# MKE15Z7 register map
Vendor: Freescale Semiconductor, Inc.; Series: Kinetis_E; File version: 1.6
CPU: CM0PLUS r0p0, little endian, no MPU, no FPU, VTOR, 2 interrupt priority bits
Registers are 32-bit, read-write, reset 0x0 unless marked. A register's access mark holds for its fields unless they carry their own. Offsets are from the block's base; [hi:lo] are bit positions; {n}, {i} and the like mark numbered series.

## SMC — System Mode Controller
Base 0x4007E000; register names take the prefix SMC_
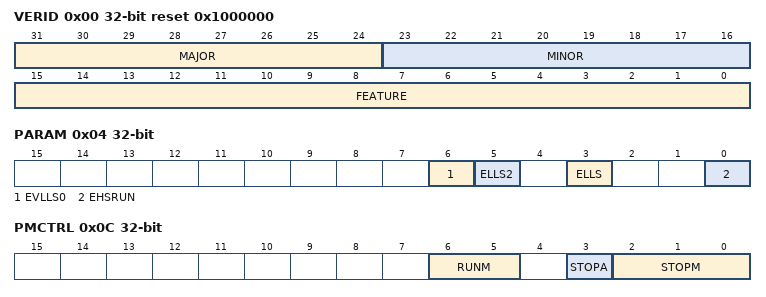
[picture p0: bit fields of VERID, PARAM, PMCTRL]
0x00 VERID ro reset 0x1000000 — SMC Version ID Register
  [31:24] MAJOR — Major Version Number
  [23:16] MINOR — Minor Version Number
  [15:0] FEATURE — Feature Specification Number
    0=Standard features implemented
0x04 PARAM ro — SMC Parameter Register
  [all] fields
    0=The feature is not available; 1=The feature is available
  [6] EVLLS0 — Existence of VLLS0 feature
  [5] ELLS2 — Existence of LLS2 feature
  [3] ELLS — Existence of LLS feature
  [0] EHSRUN — Existence of HSRUN feature
0x08 PMPROT — Power Mode Protection register
  [5] AVLP — Allow Very-Low-Power Modes
    0=VLPR, VLPW, and VLPS are not allowed; 1=VLPR, VLPW, and VLPS are allowed
0x0C PMCTRL — Power Mode Control register
  [6:5] RUNM — Run Mode Control
    0=Normal Run mode (RUN); 2=Very-Low-Power Run mode (VLPR)
  [3] STOPA ro — Stop Aborted
    0=The previous stop mode entry was successful; 1=The previous stop mode entry was aborted
  [2:0] STOPM — Stop Mode Control
    0=Normal Stop (STOP); 2=Very-Low-Power Stop (VLPS); 6=Reseved
0x10 STOPCTRL reset 0x3 — Stop Control Register
  [7:6] PSTOPO — Partial Stop Option
    0=STOP - Normal Stop mode; 1=PSTOP1 - Partial Stop with both system and bus clocks disabled; 2=PSTOP2 - Partial Stop with system clock disabled and bus clock enabled
0x14 PMSTAT ro reset 0x1 — Power Mode Status register
  [7:0] PMSTAT — Power Mode Status

## GPIOA — General Purpose Input/Output
Base 0x400FF000; register names take the prefix GPIOA_
0x00 PDOR — Port Data Output Register
  [31:0] PDO — Port Data Output
    0=Logic level 0 is driven on pin, provided pin is configured for general-purpose output; 1=Logic level 1 is driven on pin, provided pin is configured for general-purpose output
0x04 PSOR wo — Port Set Output Register
  [31:0] PTSO — Port Set Output
    0=Corresponding bit in PDORn does not change; 1=Corresponding bit in PDORn is set to logic 1
0x08 PCOR wo — Port Clear Output Register
  [31:0] PTCO — Port Clear Output
    0=Corresponding bit in PDORn does not change; 1=Corresponding bit in PDORn is cleared to logic 0
0x0C PTOR wo — Port Toggle Output Register
  [31:0] PTTO — Port Toggle Output
    0=Corresponding bit in PDORn does not change; 1=Corresponding bit in PDORn is set to the inverse of its existing logic state
0x10 PDIR ro — Port Data Input Register
  [31:0] PDI — Port Data Input
    0=Pin logic level is logic 0, or is not configured for use by digital function; 1=Pin logic level is logic 1
0x14 PDDR — Port Data Direction Register
  [31:0] PDD — Port Data Direction
    0=Pin is configured as general-purpose input, for the GPIO function; 1=Pin is configured as general-purpose output, for the GPIO function

## GPIOB — General Purpose Input/Output
Base 0x400FF040; register names take the prefix GPIOB_
Registers as GPIOA.

## GPIOC — General Purpose Input/Output
Base 0x400FF080; register names take the prefix GPIOC_
Registers as GPIOA.

## GPIOD — General Purpose Input/Output
Base 0x400FF0C0; register names take the prefix GPIOD_
Registers as GPIOA.

## GPIOE — General Purpose Input/Output
Base 0x400FF100; register names take the prefix GPIOE_
Registers as GPIOA.

## MTB — Micro Trace Buffer
Base 0xF0000000; register names take the prefix MTB_
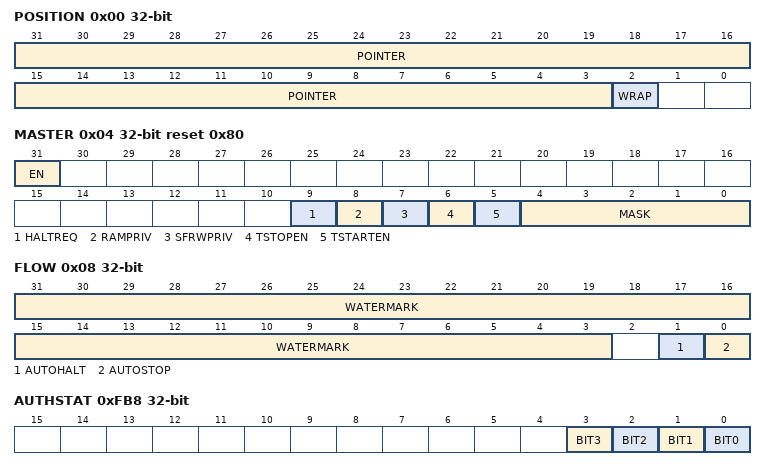
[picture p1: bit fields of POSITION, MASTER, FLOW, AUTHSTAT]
0x00 POSITION (reset mask 0x3) — MTB Position Register
  [31:3] POINTER — Trace Packet Address Pointer[28:0]
  [2] WRAP
0x04 MASTER reset 0x80 (reset mask 0xFFFFFFE0) — MTB Master Register
  [31] EN — Main Trace Enable
  [9] HALTREQ — Halt Request
  [8] RAMPRIV — RAM Privilege
  [7] SFRWPRIV — Special Function Register Write Privilege
  [6] TSTOPEN — Trace Stop Input Enable
  [5] TSTARTEN — Trace Start Input Enable
  [4:0] MASK
0x08 FLOW (reset mask 0x4) — MTB Flow Register
  [31:3] WATERMARK — WATERMARK[28:0]
  [1] AUTOHALT
  [0] AUTOSTOP
0x0C BASE ro reset not defined — MTB Base Register
  [31:0] BASEADDR
0xF00 MODECTRL ro — Integration Mode Control Register
0xFA0 TAGSET ro — Claim TAG Set Register
0xFA4 TAGCLEAR ro — Claim TAG Clear Register
0xFB0 LOCKACCESS ro
  [31:0] LOCKACCESS — Hardwired to 0x0000_0000
0xFB4 LOCKSTAT ro — Lock Status Register
0xFB8 AUTHSTAT ro — Authentication Status Register
  [3] BIT3
  [2] BIT2
  [1] BIT1
  [0] BIT0 — Connected to DBGEN.
0xFBC DEVICEARCH ro reset 0x47700A31 — Device Architecture Register
0xFC8 DEVICECFG ro — Device Configuration Register
0xFCC DEVICETYPID ro reset 0x31 — Device Type Identifier Register
0xFD0 PERIPHID{x} (x=4,5,6,7,0,1,2,3; step 0x4) ro reset not defined — Peripheral ID Register
  [31:0] PERIPHID
{0xFF0+4i} COMPID{i} (i=0..3) ro reset not defined — Component ID Register
  [31:0] COMPID — Component ID
